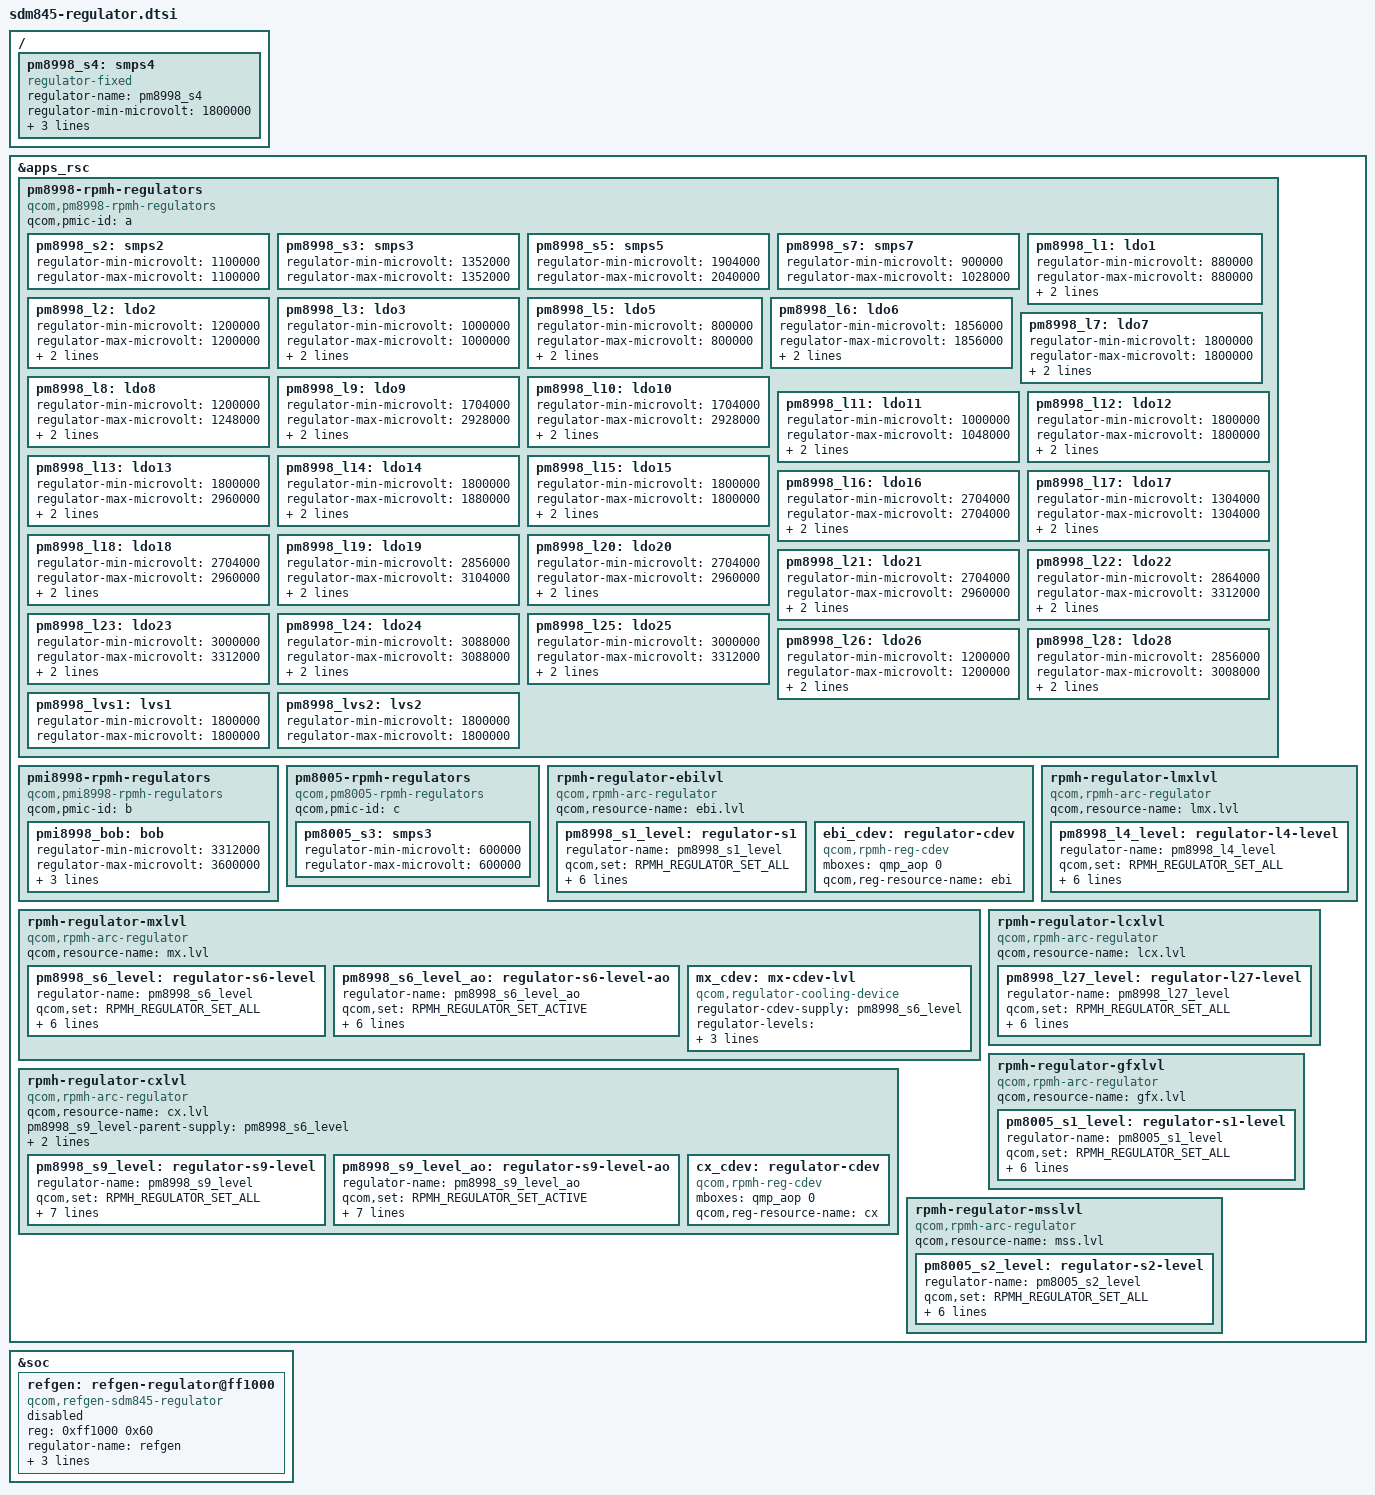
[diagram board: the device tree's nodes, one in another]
// SPDX-License-Identifier: GPL-2.0-only
/*
 * Copyright (c) 2016-2018, The Linux Foundation. All rights reserved.
 */

#include <dt-bindings/gpio/gpio.h>
#include <dt-bindings/regulator/qcom,rpmh-regulator-levels.h>

/* Stub regulators */
/ {

	/*
	 * RPMh does not provide support for PM8998 S4 because it is always-on
	 * at 1.8 V in auto mode.  Therefore, use a stub regulator for S4.
	 */
	pm8998_s4: smps4 {
		compatible = "regulator-fixed";
		regulator-name = "pm8998_s4";

		regulator-min-microvolt = <1800000>;
		regulator-max-microvolt = <1800000>;

		regulator-always-on;
		regulator-boot-on;
	};
};

/* RPMh regulators */
&apps_rsc {
	pm8998-rpmh-regulators {
		compatible = "qcom,pm8998-rpmh-regulators";
		qcom,pmic-id = "a";

		pm8998_s2: smps2 {
			regulator-min-microvolt = <1100000>;
			regulator-max-microvolt = <1100000>;
		};

		pm8998_s3: smps3 {
			regulator-min-microvolt = <1352000>;
			regulator-max-microvolt = <1352000>;
		};

		pm8998_s5: smps5 {
			regulator-min-microvolt = <1904000>;
			regulator-max-microvolt = <2040000>;
		};

		pm8998_s7: smps7 {
			regulator-min-microvolt = <900000>;
			regulator-max-microvolt = <1028000>;
		};

		pm8998_l1: ldo1 {
			regulator-min-microvolt = <880000>;
			regulator-max-microvolt = <880000>;
			regulator-initial-mode = <RPMH_REGULATOR_MODE_HPM>;
		};

		pm8998_l2: ldo2 {
			regulator-min-microvolt = <1200000>;
			regulator-max-microvolt = <1200000>;
			regulator-initial-mode = <RPMH_REGULATOR_MODE_HPM>;
		};

		pm8998_l3: ldo3 {
			regulator-min-microvolt = <1000000>;
			regulator-max-microvolt = <1000000>;
			regulator-initial-mode = <RPMH_REGULATOR_MODE_HPM>;
		};

		pm8998_l5: ldo5 {
			regulator-min-microvolt = <800000>;
			regulator-max-microvolt = <800000>;
			regulator-initial-mode = <RPMH_REGULATOR_MODE_HPM>;
		};

		pm8998_l6: ldo6 {
			regulator-min-microvolt = <1856000>;
			regulator-max-microvolt = <1856000>;
			regulator-initial-mode = <RPMH_REGULATOR_MODE_HPM>;
		};

		pm8998_l7: ldo7 {
			regulator-min-microvolt = <1800000>;
			regulator-max-microvolt = <1800000>;
			regulator-initial-mode = <RPMH_REGULATOR_MODE_HPM>;
		};

		pm8998_l8: ldo8 {
			regulator-min-microvolt = <1200000>;
			regulator-max-microvolt = <1248000>;
			regulator-initial-mode = <RPMH_REGULATOR_MODE_HPM>;
		};

		pm8998_l9: ldo9 {
			regulator-min-microvolt = <1704000>;
			regulator-max-microvolt = <2928000>;
			regulator-initial-mode = <RPMH_REGULATOR_MODE_HPM>;
		};

		pm8998_l10: ldo10 {
			regulator-min-microvolt = <1704000>;
			regulator-max-microvolt = <2928000>;
			regulator-initial-mode = <RPMH_REGULATOR_MODE_HPM>;
		};

		pm8998_l11: ldo11 {
			regulator-min-microvolt = <1000000>;
			regulator-max-microvolt = <1048000>;
			regulator-initial-mode = <RPMH_REGULATOR_MODE_HPM>;
		};

		pm8998_l12: ldo12 {
			regulator-min-microvolt = <1800000>;
			regulator-max-microvolt = <1800000>;
			regulator-initial-mode = <RPMH_REGULATOR_MODE_HPM>;
		};

		pm8998_l13: ldo13 {
			regulator-min-microvolt = <1800000>;
			regulator-max-microvolt = <2960000>;
			regulator-initial-mode = <RPMH_REGULATOR_MODE_HPM>;
		};

		pm8998_l14: ldo14 {
			regulator-min-microvolt = <1800000>;
			regulator-max-microvolt = <1880000>;
			regulator-initial-mode = <RPMH_REGULATOR_MODE_HPM>;
		};

		pm8998_l15: ldo15 {
			regulator-min-microvolt = <1800000>;
			regulator-max-microvolt = <1800000>;
			regulator-initial-mode = <RPMH_REGULATOR_MODE_HPM>;
		};

		pm8998_l16: ldo16 {
			regulator-min-microvolt = <2704000>;
			regulator-max-microvolt = <2704000>;
			regulator-initial-mode = <RPMH_REGULATOR_MODE_HPM>;
		};

		pm8998_l17: ldo17 {
			regulator-min-microvolt = <1304000>;
			regulator-max-microvolt = <1304000>;
			regulator-initial-mode = <RPMH_REGULATOR_MODE_HPM>;
		};

		pm8998_l18: ldo18 {
			regulator-min-microvolt = <2704000>;
			regulator-max-microvolt = <2960000>;
			regulator-initial-mode = <RPMH_REGULATOR_MODE_HPM>;
		};

		pm8998_l19: ldo19 {
			regulator-min-microvolt = <2856000>;
			regulator-max-microvolt = <3104000>;
			regulator-initial-mode = <RPMH_REGULATOR_MODE_HPM>;
		};

		pm8998_l20: ldo20 {
			regulator-min-microvolt = <2704000>;
			regulator-max-microvolt = <2960000>;
			regulator-initial-mode = <RPMH_REGULATOR_MODE_HPM>;
		};

		pm8998_l21: ldo21 {
			regulator-min-microvolt = <2704000>;
			regulator-max-microvolt = <2960000>;
			regulator-initial-mode = <RPMH_REGULATOR_MODE_HPM>;
		};

		pm8998_l22: ldo22 {
			regulator-min-microvolt = <2864000>;
			regulator-max-microvolt = <3312000>;
			regulator-initial-mode = <RPMH_REGULATOR_MODE_HPM>;
		};

		pm8998_l23: ldo23 {
			regulator-min-microvolt = <3000000>;
			regulator-max-microvolt = <3312000>;
			regulator-initial-mode = <RPMH_REGULATOR_MODE_HPM>;
		};

		pm8998_l24: ldo24 {
			regulator-min-microvolt = <3088000>;
			regulator-max-microvolt = <3088000>;
			regulator-initial-mode = <RPMH_REGULATOR_MODE_HPM>;
		};

		pm8998_l25: ldo25 {
			regulator-min-microvolt = <3000000>;
			regulator-max-microvolt = <3312000>;
			regulator-initial-mode = <RPMH_REGULATOR_MODE_HPM>;
		};

		pm8998_l26: ldo26 {
			regulator-min-microvolt = <1200000>;
			regulator-max-microvolt = <1200000>;
			regulator-initial-mode = <RPMH_REGULATOR_MODE_HPM>;
		};

		pm8998_l28: ldo28 {
			regulator-min-microvolt = <2856000>;
			regulator-max-microvolt = <3008000>;
			regulator-initial-mode = <RPMH_REGULATOR_MODE_HPM>;
		};

		pm8998_lvs1: lvs1 {
			regulator-min-microvolt = <1800000>;
			regulator-max-microvolt = <1800000>;
		};

		pm8998_lvs2: lvs2 {
			regulator-min-microvolt = <1800000>;
			regulator-max-microvolt = <1800000>;
		};
	};

	pmi8998-rpmh-regulators {
		compatible = "qcom,pmi8998-rpmh-regulators";
		qcom,pmic-id = "b";

		pmi8998_bob: bob {
			regulator-min-microvolt = <3312000>;
			regulator-max-microvolt = <3600000>;
			regulator-initial-mode = <RPMH_REGULATOR_MODE_AUTO>;
			regulator-allow-bypass;
		};
	};

	pm8005-rpmh-regulators {
		compatible = "qcom,pm8005-rpmh-regulators";
		qcom,pmic-id = "c";

		pm8005_s3: smps3 {
			regulator-min-microvolt = <600000>;
			regulator-max-microvolt = <600000>;
		};
	};

	/* PM8998 S1 = VDD_EBI supply */
	rpmh-regulator-ebilvl {
		compatible = "qcom,rpmh-arc-regulator";
		qcom,resource-name = "ebi.lvl";

		pm8998_s1_level: regulator-s1 {
			regulator-name = "pm8998_s1_level";
			qcom,set = <RPMH_REGULATOR_SET_ALL>;
			regulator-min-microvolt = <RPMH_REGULATOR_LEVEL_RETENTION>;
			regulator-max-microvolt = <RPMH_REGULATOR_LEVEL_MAX>;
			qcom,init-voltage-level = <RPMH_REGULATOR_LEVEL_RETENTION>;
		};

		ebi_cdev: regulator-cdev {
			compatible = "qcom,rpmh-reg-cdev";
			mboxes = <&qmp_aop 0>;
			qcom,reg-resource-name = "ebi";
			#cooling-cells = <2>;
		};
	};

	/* PM8998 S6 = VDD_MX supply */
	rpmh-regulator-mxlvl {
		compatible = "qcom,rpmh-arc-regulator";
		qcom,resource-name = "mx.lvl";

		pm8998_s6_level: regulator-s6-level {
			regulator-name = "pm8998_s6_level";
			qcom,set = <RPMH_REGULATOR_SET_ALL>;
			regulator-min-microvolt = <RPMH_REGULATOR_LEVEL_RETENTION>;
			regulator-max-microvolt = <RPMH_REGULATOR_LEVEL_MAX>;
			qcom,init-voltage-level = <RPMH_REGULATOR_LEVEL_RETENTION>;
		};

		pm8998_s6_level_ao: regulator-s6-level-ao {
			regulator-name = "pm8998_s6_level_ao";
			qcom,set = <RPMH_REGULATOR_SET_ACTIVE>;
			regulator-min-microvolt = <RPMH_REGULATOR_LEVEL_RETENTION>;
			regulator-max-microvolt = <RPMH_REGULATOR_LEVEL_MAX>;
			qcom,init-voltage-level = <RPMH_REGULATOR_LEVEL_RETENTION>;
		};

		mx_cdev: mx-cdev-lvl {
			compatible = "qcom,regulator-cooling-device";
			regulator-cdev-supply = <&pm8998_s6_level>;
			regulator-levels = <RPMH_REGULATOR_LEVEL_NOM RPMH_REGULATOR_LEVEL_RETENTION>;
			qcom,init-voltage-level = <RPMH_REGULATOR_LEVEL_RETENTION>;
			#cooling-cells = <2>;
		};
	};

	/* PM8998 S9 + S8 = VDD_CX supply */
	rpmh-regulator-cxlvl {
		compatible = "qcom,rpmh-arc-regulator";
		qcom,resource-name = "cx.lvl";
		pm8998_s9_level-parent-supply = <&pm8998_s6_level>;
		pm8998_s9_level_ao-parent-supply = <&pm8998_s6_level_ao>;

		pm8998_s9_level: regulator-s9-level {
			regulator-name = "pm8998_s9_level";
			qcom,set = <RPMH_REGULATOR_SET_ALL>;
			regulator-min-microvolt = <RPMH_REGULATOR_LEVEL_RETENTION>;
			regulator-max-microvolt = <RPMH_REGULATOR_LEVEL_MAX>;
			qcom,init-voltage-level = <RPMH_REGULATOR_LEVEL_RETENTION>;
			qcom,min-dropout-voltage-level = <(-1)>;
		};

		pm8998_s9_level_ao: regulator-s9-level-ao {
			regulator-name = "pm8998_s9_level_ao";
			qcom,set = <RPMH_REGULATOR_SET_ACTIVE>;
			regulator-min-microvolt = <RPMH_REGULATOR_LEVEL_RETENTION>;
			regulator-max-microvolt = <RPMH_REGULATOR_LEVEL_MAX>;
			qcom,init-voltage-level = <RPMH_REGULATOR_LEVEL_RETENTION>;
			qcom,min-dropout-voltage-level = <(-1)>;
		};

		cx_cdev: regulator-cdev {
			compatible = "qcom,rpmh-reg-cdev";
			mboxes = <&qmp_aop 0>;
			qcom,reg-resource-name = "cx";
			#cooling-cells = <2>;
		};
	};

	/* PM8998 L4 = VDD_SSC_MX supply */
	rpmh-regulator-lmxlvl {
		compatible = "qcom,rpmh-arc-regulator";
		qcom,resource-name = "lmx.lvl";

		pm8998_l4_level: regulator-l4-level {
			regulator-name = "pm8998_l4_level";
			qcom,set = <RPMH_REGULATOR_SET_ALL>;
			regulator-min-microvolt = <RPMH_REGULATOR_LEVEL_RETENTION>;
			regulator-max-microvolt = <RPMH_REGULATOR_LEVEL_MAX>;
			qcom,init-voltage-level = <RPMH_REGULATOR_LEVEL_RETENTION>;
		};
	};

	/* PM8998 L27 = VDD_SSC_CX supply */
	rpmh-regulator-lcxlvl {
		compatible = "qcom,rpmh-arc-regulator";
		qcom,resource-name = "lcx.lvl";

		pm8998_l27_level: regulator-l27-level {
			regulator-name = "pm8998_l27_level";
			qcom,set = <RPMH_REGULATOR_SET_ALL>;
			regulator-min-microvolt = <RPMH_REGULATOR_LEVEL_RETENTION>;
			regulator-max-microvolt = <RPMH_REGULATOR_LEVEL_MAX>;
			qcom,init-voltage-level = <RPMH_REGULATOR_LEVEL_RETENTION>;
		};
	};

	/* PM8005 S1 + S4 = 2 phase VDD_GFX supply */
	rpmh-regulator-gfxlvl {
		compatible = "qcom,rpmh-arc-regulator";
		qcom,resource-name = "gfx.lvl";

		pm8005_s1_level: regulator-s1-level {
			regulator-name = "pm8005_s1_level";
			qcom,set = <RPMH_REGULATOR_SET_ALL>;
			regulator-min-microvolt = <RPMH_REGULATOR_LEVEL_MIN_SVS>;
			regulator-max-microvolt = <RPMH_REGULATOR_LEVEL_MAX>;
			qcom,init-voltage-level = <RPMH_REGULATOR_LEVEL_MIN_SVS>;
		};
	};

	/* PM8005 S2 = VDD_MODEM supply */
	rpmh-regulator-msslvl {
		compatible = "qcom,rpmh-arc-regulator";
		qcom,resource-name = "mss.lvl";

		pm8005_s2_level: regulator-s2-level {
			regulator-name = "pm8005_s2_level";
			qcom,set = <RPMH_REGULATOR_SET_ALL>;
			regulator-min-microvolt = <RPMH_REGULATOR_LEVEL_RETENTION>;
			regulator-max-microvolt = <RPMH_REGULATOR_LEVEL_MAX>;
			qcom,init-voltage-level = <RPMH_REGULATOR_LEVEL_RETENTION>;
		};
	};
};

&soc {
	refgen: refgen-regulator@ff1000 {
		compatible = "qcom,refgen-sdm845-regulator";
		reg = <0xff1000 0x60>;
		regulator-name = "refgen";
		regulator-enable-ramp-delay = <5>;
		status = "disabled";
		proxy-supply = <&refgen>;
		qcom,proxy-consumer-enable;
	};
};
